# USB0_COMMON_0_VBP2APB_WRAP_CONTROLLER_VBP_CORE_ADDR_MAP register map
Vendor: Texas Instruments
Registers are 32-bit, access per field, reset 0x0 unless marked. A register's access mark holds for its fields unless they carry their own. Offsets are as the file gives them; [hi:lo] are bit positions; 'fields as' and 'values as' point back to an identical list.

## USB0_COMMON_0_VBP2APB_WRAP_CONTROLLER_VBP_CORE_ADDR_MAP (part 2 of 8)
0x00 VBP2APB_WRAP__CONTROLLER_VBP__CORE_ADDR_MAP_CDNS_DID ro reset 0x4024E
  [31:0] DID — Cadence Device ID Register IP4024E
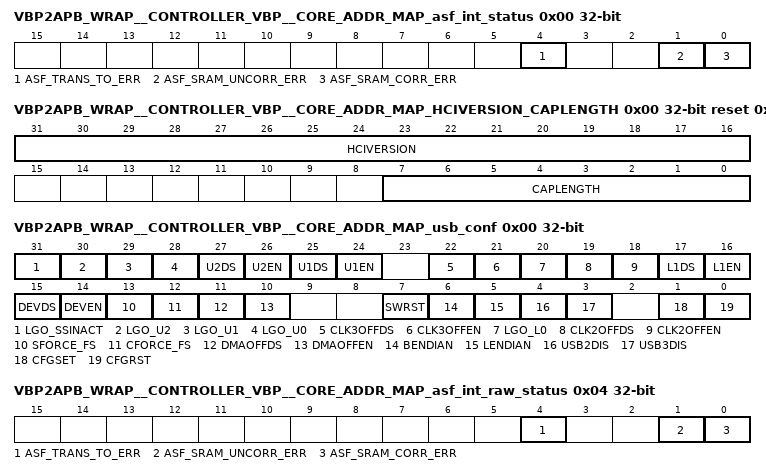
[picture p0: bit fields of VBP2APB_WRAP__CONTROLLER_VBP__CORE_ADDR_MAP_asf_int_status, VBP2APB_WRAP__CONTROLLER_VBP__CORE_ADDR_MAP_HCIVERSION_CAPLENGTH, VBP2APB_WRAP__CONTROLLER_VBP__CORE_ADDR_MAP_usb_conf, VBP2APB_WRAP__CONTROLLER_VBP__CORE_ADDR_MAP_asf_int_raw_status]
0x00 VBP2APB_WRAP__CONTROLLER_VBP__CORE_ADDR_MAP_asf_int_status access not given
  [4] ASF_TRANS_TO_ERR — Transaction timeouts error interrupt (access R/W1TC)
  [1] ASF_SRAM_UNCORR_ERR — SRAM uncorrectable error interrupt (access R/W1TC)
  [0] ASF_SRAM_CORR_ERR — SRAM correctable error interrupt (access R/W1TC)
0x00 VBP2APB_WRAP__CONTROLLER_VBP__CORE_ADDR_MAP_HCIVERSION_CAPLENGTH ro reset 0x1000080
  [31:16] HCIVERSION — Host Controller Interface Version Number [HCIVERSION]. This is a two-byte register containing a BCD encoding of the xHCI specification revision number supported by this host controller. The most significant byte of this register represents a major revision and the least significant byte is the minor revision. e.g. 0100h corresponds to xHCI version 1.0.
  [7:0] CAPLENGTH — Capability Registers Length [CAPLENGTH]. This register is used as an offset to add to register base to find the beginning of the Operational Register Space.
0x00 VBP2APB_WRAP__CONTROLLER_VBP__CORE_ADDR_MAP_usb_conf
  [31] LGO_SSINACT rw — SS.Inactive state entry request [SS mode only]. This bit can be used only if USBSS-DEV is part of the CDNS USB OTG Controller [USB_CAP.OTG_READY bit is 1 while reading]. In other cases should not be used and returns 0 when read. Writing '1' will trigger an attempt to perform transition to SS.Inactive state. Should be used only if Link is in U0 or Recovery state. This bit will be automatically cleared to '0' after link layer finishes SS.Inactive request. Result of the request [link layer enters SS.Inactive or not] can be verified by reading LTS [link state] field in USB_STS register. Writing '0' has no effect
  [30] LGO_U2 rw — U2 state entry request [SS mode only]. Writing '1' will trigger an attempt to perform transition to U2 state. This bit will be automatically cleared to '0' after link layer finishes U2 request. Result of the request [link layer enters U2 or not] can be verified by reading LTS [link state] field in USB_STS register. Writing '1' has no effect when USB_STS.LGOU2ENS is set to '0'. Writing '0' has no effect.
  [29] LGO_U1 rw — U1 state entry request [SS mode only]. Writing '1' will trigger an attempt to perform transition to U1 state. This bit will be automatically cleared to '0' after link layer finishes U1 request. Result of the request [link layer enters U1 or not] can be verified by reading LTS [link state] field in USB_STS register. Writing '1' has no effect when USB_STS.LGOU1ENS is set to '0'. Writing '0' has no effect.
  [28] LGO_U0 rw — U0 state entry request [SS mode only]. Writing '1' will trigger an attempt to perform transition to U0 state. If the link is suspended [U3 state] and CPU set this bit to'1', link will start driving resume signaling on its upstream link to indicate remote wakeup. The Function Wake Notification should be send using USB_CMD.SDNFW bit. Writing '0' has no effect.
  [27] U2DS wo — U2 state entry disable [SS mode only]. Writing '1' to this bit disables link layer from entering U2 state. Status of this bit can be checked in the USB_STS register. When both U2EN and U2DS bits are set to '1' while writing to USB_CONF register, the device behaviour is udefined. Writing '0' has no effect. This bit is always '0' while reading.
  [26] U2EN wo — U2 state entry enable [device side, SS mode only]. Writing '1' to this bit enables link layer to enter U2 state. Status of this bit can be checked in the USB_STS register. Writing '0' has no effect. When both U2EN and U2DS bits are set to '1' while writing to USB_CONF register, the device behaviour is udefined. This bit is always '0' while reading.
  [25] U1DS wo — U1 state entry disable [SS mode only]. Writing '1' to this bit disables link layer from entering U1 state. Status of this bit can be checked in the USB_STS register. Writing '0' has no effect. When both U1EN and U1DS bits are set to '1' while writing to USB_CONF register, none of the operations associated with these bits will be performed. This bit is always '0' while reading.
  [24] U1EN wo — U1 state entry enable [device side, SS mode only], Writing '1' to this bit enables link layer to enter U1 state. Status of this bit can be checked in the USB_STS register. Writing '0' has no effect. When both U1EN and U1DS bits are set to '1' while writing to USB_CONF register, none of the operations associated with these bits will be performed. This bit is always '0' while reading.
  [22] CLK3OFFDS wo — USB 3.0 clock gate enable. Writing '1' to this bit disables pclk clock turning-off when device enters U3 link state in SS mode. The actual 'USB 3.0 clock gate' status in can be checked in the USB_STS.USB3OFF register. When both CLK3OFFDS and CLK3OFFEN bits are set to '1' while writing to USB_CONF register, the device behaviour is udefined. This bit is always '0' while reading.
  [21] CLK3OFFEN wo — USB 3.0 clock gate disable. Writing '1' to this bit enables pclk clock turning-off when device enters U3 link state in SS mode. The actual 'USB 3.0 clock gate' status in can be checked in the USB_STS.USB3OFF register. When both CLK3OFFDS and CLK3OFFEN bits are set to '1' while writing to USB_CONF register, the device behaviour is udefined. This bit is always '0' while reading.
  [20] LGO_L0 rw — L0 LPM state entry request [HS/FS mode only]. Writing '1' will trigger an attempt to perform transition to L0 LPM state. This bit will be automatically cleared to '0' after LPM enter L0 state. Result of the request [LPM enters L0 or not] can be verified by reading LPMST [LPM state] field in USB_STS register. Writing '0' has no effect. If the LPM is suspended [L2 state] and CPU set this bit to'1', upstream will start driving resume signaling to indicate remote wakeup.
  [19] CLK2OFFDS wo — USB 2.0 clock gate enable. Writing '1' to this bit disables hsfs clock turning-off when device enters L2 LPM state in HS/FS mode. The actual 'USB 2.0 clock gate' status in can be checked in the USB_STS.USB2OFF register. When both CLK2OFFDS and CLK2OFFEN bits are set to '1' while writing to USB_CONF register, the device behaviour is udefined. This bit is always '0' while reading.
  [18] CLK2OFFEN wo — USB 2.0 clock gate disable. Writing '1' to this bit enables hsfs clock turning-off when device enters L2 LPM state in HS/FS mode. The actual 'USB 2.0 clock gate' status in can be checked in the USB_STS.USB2OFF register. When both CLK2OFFDS and CLK2OFFEN bits are set to '1' while writing to USB_CONF register, the device behaviour is udefined. This bit is always '0' while reading.
  [17] L1DS wo — L1 LPM state entry disable [HS/FS mode only]. Writing '1' to this bit disables USB2.0 LPM from entering L1 state. Status of this bit can be checked in the USB_STS register. Writing '0' has no effect. When both L1EN and L1DS bits are set to '1' while writing to USB_CONF register, the device behaviour is udefined. This bit is always '0' while reading.
  [16] L1EN wo — L1 LPM state entry enable [device side, HS/FS mode only]. Writing '1' to this bit enables USB2.0 LPM to enter L1 state. Status of this bit can be checked in the USB_STS register. Writing '0' has no effect. When both L1EN and L1DS bits are set to '1' while writing to USB_CONF register, the device behaviour is udefined. This bit is always '0' while reading.
  [15] DEVDS wo — Device disable. Writing '1' to the DEVDS bit sets to '0' the USB_STS.DEVS bit. Check also the DEVEN bit description. Writing '0' has no effect. This bit is always '0' while reading.
  [14] DEVEN wo — Device enable. After Power-On-Reset the USBSS_DEV is disconnected from the USB bus. To connect the device into the USB bus the software has to write '1' to DEVEN bit - this couse connection of the VBUS input to the internal device logic and connetion to the USB bus as a result [inside of USBSS_DEV an internal VBUS is used which which is the and gate: VBUS input AND USB_STS.DEVS bit in SFRs]. Writing '1' to the DEVEN bit sets to '1' the USB_STS.DEVS bit. Writing '0' has no effect. This bit is always '0' while reading.
  [13] SFORCE_FS wo — Set Force Full Speed. Writing '1' to this bit forces Full Speed when USBSS-DEV operates in USB2.0 mode [disables High Speed]. When both SFORCE_FS and CFORCE_FS bits are set to '1' while writing to USB_CONF register, the device behaviour is udefined. The status of this settings can be check in the USB_STS.DISABLE_HS bit. This bit is always '0' while reading.
  [12] CFORCE_FS wo — Clear Force Full Speed. Writing '1' to this bit stop forcing Full Speed when USBSS-DEV operates in USB2.0 mode [stop disabling High Speed]. When both SFORCE_FS and CFORCE_FS bits are set to '1' while writing to USB_CONF register, the device behaviour is udefined. The status of this settings can be check in the USB_STS.DISABLE_HS bit. This bit is always '0' while reading.
  [11] DMAOFFDS wo — DMA clock turn-off disable. Writing '1' to this bit disables DMA clock turning-off when device exits U0 link state in SuperSpeed mode. When both DMAOFFDS and DMAOFFEN bits are set to '1' while writing to USB_CONF register, the device behaviour is udefined. This bit is always '0' while reading.
  [10] DMAOFFEN wo — DMA clock turn-off enable. Writing '1' to this bit enables DMA clock turning-off when device exits U0 link state in SuperSpeed mode. When both DMAOFFDS and DMAOFFEN bits are set to '1' while writing to USB_CONF register, the device behaviour is udefined. This bit is always '0' while reading.
  [7] SWRST rw — Device software reset. When set to 1, the entire USBSS-DEV is reset. The SWRST resets most flip-flops in entire USBSS-DEV. This bit is also used to connect disconnected device. Writing '0' has no effect.
  [6] BENDIAN wo — Big Endian Access. Writing '1' to this bit sets Big Endian byte order for SFRs access. Writing '0' has no effect. When both LENDIAN and BENDIAN bits are set to '1' while writing to USB_CONF register, the device behaviour is udefined. This bit is always '0' while reading.
  [5] LENDIAN wo — Little Endian access. Writing '1' to this bit sets Little Endian byte order for SFRs access. By default [after hardware reset], USBSS-DEV acts as little-endian device. Writing '0' has no effect. When both LENDIAN and BENDIAN bits are set to '1' while writing to USB_CONF register, the device behaviour is udefined. This bit is always '0' while reading.
  [4] USB2DIS wo — Disconnect USB device in HS/FS. Writing '1' to this bit disconnects USB in HS/FS. The actual USB connection status in HS/FS can be checked in the USB_STS register. Writing '0' has no effect. To connect disconnected device, CPU performs software reset [UCB_CFG.SWRST]. This bit is always '0' while reading.
  [3] USB3DIS wo — Disconnect USB device in SuperSpeed. Writing '1' to this bit disconnects USB in Super Speed. The actual USB connection status in the SS mode can be checked in the USB_STS register. If link is in U3 [SuperSpeed PHY clock is disabled] while software writes USB3DIS bit, first the hardware automatically wakes up the PHY to the P2 to turn on the PHY clock [clklink], and second, all operations related to device disconnection cease. Writing '0' has no effect. To connect disconnected device, CPU performs software reset [UCB_CFG.SWRST]. This bit is always '0' while reading.
  [1] CFGSET wo — Set Configuration. Software writes '1' to this bit when it receives SET_CONFIGURATION request with non-zero configuration number. CPU sets this bit after setting requested configuration and before setting REQ_CMPL bit in the EP_CMD register. Configuration will be set internally in the hardware when REQ_CMPL bit will be set. Writing '0' has no effect. The actual configuration status can be checked in the USB_STS register. This bit is always '0' while reading.
  [0] CFGRST wo — Reset USB device configuration. Writing '1' to this bit resets USB device configuration, leaving only EP0 IN/OUT active [all other EP-related registers will be loaded with default values]. Any configuration/interface change, including adding new IF, must be preceded with configuration reset, adding current IF's as well as new IF. Writing '0' has no effect. This bit is always '0' while reading.
0x04 VBP2APB_WRAP__CONTROLLER_VBP__CORE_ADDR_MAP_CDNS_RID ro reset 0x200
  [15:0] CDNS_RID
0x04 VBP2APB_WRAP__CONTROLLER_VBP__CORE_ADDR_MAP_asf_int_raw_status access not given
  fields as VBP2APB_WRAP__CONTROLLER_VBP__CORE_ADDR_MAP_asf_int_status
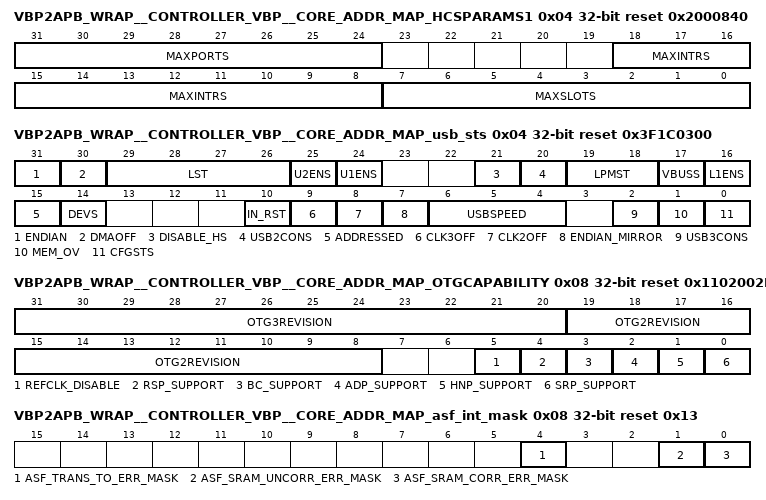
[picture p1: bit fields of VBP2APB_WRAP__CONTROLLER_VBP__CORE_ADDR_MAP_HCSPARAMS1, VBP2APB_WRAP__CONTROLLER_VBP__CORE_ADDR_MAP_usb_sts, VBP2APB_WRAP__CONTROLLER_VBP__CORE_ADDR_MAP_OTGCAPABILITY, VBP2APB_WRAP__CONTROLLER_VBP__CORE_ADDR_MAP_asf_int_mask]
0x04 VBP2APB_WRAP__CONTROLLER_VBP__CORE_ADDR_MAP_HCSPARAMS1 ro reset 0x2000840
  [31:24] MAXPORTS — Number of Ports [MaxPorts]. This field specifies the maximum Port Number value, i.e. the highest numbered Port Register Set that are addressable in the Operational Register Space. Valid values are in the range of 1h to FFh. The value in this field shall reflect the maximum Port Number value assigned by an xHCI Supported Protocol Capability, described in section 7.2 of xHCI specification. Software shall refer to these capabilities to identify whether a specific Port Number is valid, and the protocol supported by the associated Port Register Set.
  [18:8] MAXINTRS — Number of Interrupters [MaxIntrs]. This field specifies the number of Interrupters implemented on this host controller. Each Interrupter may be allocated to a MSI or MSI-X vector and controls its generation and moderation. The value of this field determines how many Interrupter Register Sets are addressable in the Runtime Register Space [refer to section 5.5 of xHCI specification]. Valid values are in the range of 1h to 400h. A '0' in this field is undefined.
  [7:0] MAXSLOTS — Number of Device Slots [MaxSlots]. This field specifies the maximum number of Device Context Structures and Doorbell Array entries this host controller can support. Valid values are in the range of 1 to 255. The value of 0 is reserved.
0x04 VBP2APB_WRAP__CONTROLLER_VBP__CORE_ADDR_MAP_usb_sts ro reset 0x3F1C0300
  [31] ENDIAN — SFR Endian status. Little/Big Endian byte order for SFR access: 0 - Little Endian order [default after hardware reset] 1 - Big Endian order
  [30] DMAOFF — DMA clock turn-off status. DMA clock turn-off/enable status: 0 - DMA clock is always on [default after hardware reset] 1 - DMA clock turn-off in U1, U2 and U3 [SS mode] is enabled.
  [29:26] LST — SuperSpeed Link LTSSM state. This field reflects USBSS-DEV current SuperSpeed link state: 0 - U0 State 1 - U1 State 2 - U2 State 3 - U3 State [Device Suspended] 4 - Disabled State 5 - RxDetect State 6 - Inactive State 7 - Polling State 8 - Recovery State 9 - Hot Reset State 10 - Compliance Mode State 11 - Loopback State 12:14 - Reserved 15 - Uninitialized
  [25] U2ENS — U2 state enable status [valid in SS mode only]: 0 - Entering to U2 state disabled 1 - Entering to U2 state enabled
  [24] U1ENS — U1 state enable status [valid in SS mode only]: 0 - Entering to U1 state disabled 1 - Entering to U1 state enabled
  [21] DISABLE_HS — DisableHS status [valid for HS/FS mode only] 0 - High Speed operations in USB2.0 [FS/HS] mode not disabled 1 - High Speed operations in USB2.0 [FS/HS] mode disabled
  [20] USB2CONS — HS/FS mode connection enable status [valid for HS/FS mode only]. 0 - the disconnect bit for HS/FS mode is set [USB_CONF.USB2DIS] 1 - the disconnect bit for HS/FS mode is not set [device can be connected in this mode] The actual connection status can be checked in the USB_STS.USBSPEED register
  [19:18] LPMST — HS/FS LPM state [valid for HS/FS mode only]. This field reflects USBSS-DEV current LPM [used in HS/FS mode] state: 0 - L0 State 1 - L1 State 2 - L2 State 3 - L3 State
  [17] VBUSS — Internal VBUS connection status. 0 - internal VBUS is not detected 1 - internal VBUS is detected
  [16] L1ENS — L1 LPM state enable status [valid for HS/FS mode only]. 0 - Entering to L1 LPM state disabled 1 - Entering to L1 LPM state enabled
  [15] ADDRESSED — Address status: 0 - USB device is default state 1 - USB device is at least in address state [Function Address was set by the SW]
  [14] DEVS — Device enable Status 0 - USB device is disabled [VBUS input is disconnected from internal logic] 1 - USB device is enabled [VBUS input is connected to the internal logic] This bit can be changed by setting DEVEN or DEVDS bits in USB_CONF register.
  [10] IN_RST — Controler in reset state. This bit indicate that whole [in case of POR] or part of controller [in case of SWRST or USB resets] currently is in reset state. As controller has registers in both clock domains [system, and USB], internal reset synchronization between these domains may take longer than the cause of the reset [e.g active reset_n input]. Thus it is recommended to check if controller is not in reset state, before software starts its operations [especially after POR]. 0 - Internal reset is active 1 - Internal reset is not active and controller is fully operational.
  [9] CLK3OFF — PCLK clock turn-off status. When CLK3OFF bit is '0', the phypowerdown output signal is not set to '11' in U3 link state, thus USB3.0 PHY does not turn off the pclk clock. 0 - pclk clock is always on 1 - pclk clock turn-off in U3 [SS mode] is enabled [default after hardware reset]
  [8] CLK2OFF — HS/FS clock turn-off status. When CLK2OFF bit is '0', the utmisuspendm output signal is not set low in USB2.0 suspend state [L2 state], thus USB2.0 PHY does not turn off the hsfs clock 0 - hsfs clock is always on 1 - hsfs clock turn-off in L2 [HS/FS mode] is enabled [default after hardware reset]
  [7] ENDIAN_MIRROR — Little/Big Endian byte order for SFR access. 0 - Little Endian order [default after hardware reset] 1 - Big Endian order Endian byte order for SFR access can be changed by setting BENDIAN or LEDNIAN bits in USB_CONF register.
  [6:4] USBSPEED — Device speed: 0: undef., 1: LowSpeed [not supported], 2: FullSpeed, 3: HighSpeed, 4: SuperSpeed, 5-7: Reserved
  [2] USB3CONS — SuperSpeed connection status. 0 - USB in SuperSpeed mode disconnected 1 - USB in SuperSpeed mode connected
  [1] MEM_OV — On-chip memory overflow. 0 - On-chip memory status OK 1 - On-chip memory overflow Memory overflow may occur if, during enumeration [SET_CONFIGURATION request] device software will try to turn on too many endpoints or will try to set too much endpoinds buffers [see EP_CFG.BUFFERING]. After each completion of enumeration software should check this bit, and when a memory overflow occurred, software must delete current configuration [using USB_CONF.CFGRST bit] and then set the one that requires less on-chip memory. For available memory calculation, the CDNS_USBSSDEV_ATTACHED_MEM_SIZE define parameter is used.
  [0] CFGSTS — Configuration status. 1 - device is in the configured state 0 - device is not configured This bit set during SET_CONFIGURATION request means that status stage of this request was finished successfully, thus device configuration was finished successfully.
0x08 VBP2APB_WRAP__CONTROLLER_VBP__CORE_ADDR_MAP_OTGCAPABILITY ro reset 0x1102002B
  [31:20] OTG3REVISION — Specifies implemeted OTG3.0 specification revision
  [19:8] OTG2REVISION — Specifies implemeted OTG2.0 specification revision
  [5] REFCLK_DISABLE — PHY Reference clock control disable. 0 - PHY Reference clock control supported 1 - PHY Reference clock control not supported
  [4] RSP_SUPPORT — RSP support. 0 - RSP not supported 1 - RSP supported
  [3] BC_SUPPORT — BC Support [Battery Charging specification rev 1.2]. 0 - BC not supported 1 - BC supported
  [2] ADP_SUPPORT — ADP support. 0 - ADP not supported 1 - ADP supported
  [1] HNP_SUPPORT — HNP support. 0 - HNP not supported 1 - HNP supported
  [0] SRP_SUPPORT — SRP support. 0 - SRP not supported 1 - SRP supported
0x08 VBP2APB_WRAP__CONTROLLER_VBP__CORE_ADDR_MAP_asf_int_mask reset 0x13
  [4] ASF_TRANS_TO_ERR_MASK rw — Mask bit for transaction timeouts error interrupt.
  [1] ASF_SRAM_UNCORR_ERR_MASK rw — Mask bit for SRAM uncorrectable error interrupt.
  [0] ASF_SRAM_CORR_ERR_MASK rw — Mask bit for SRAM correctable error interrupt.
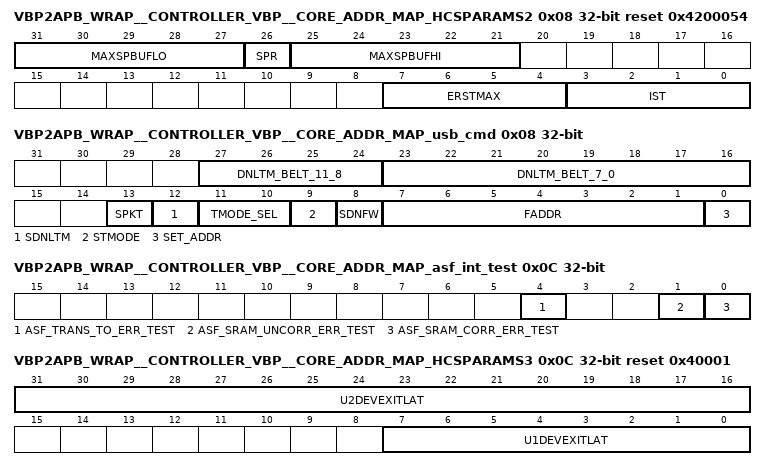
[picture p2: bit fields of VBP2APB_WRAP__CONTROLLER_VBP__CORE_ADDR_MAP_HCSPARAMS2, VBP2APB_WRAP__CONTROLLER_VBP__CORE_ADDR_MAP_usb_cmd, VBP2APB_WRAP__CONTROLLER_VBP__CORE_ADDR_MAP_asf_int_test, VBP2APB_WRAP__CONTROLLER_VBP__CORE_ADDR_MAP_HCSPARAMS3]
0x08 VBP2APB_WRAP__CONTROLLER_VBP__CORE_ADDR_MAP_HCSPARAMS2 ro reset 0x4200054
  [31:27] MAXSPBUFLO — Max Scratchpad Buffers [Max Scratchpad Bufs Lo]. Default = implementation dependent. Valid values for Max Scratchpad Buffers [Hi and Lo] are 0-1023. This field indicates the low order 5 bits of the number of Scratchpad Buffers system software shall reserve for the xHC. Refer to section 4.20 of xHCI specification for more information.
  [26] SPR — Scratchpad Restore [SPR]. Default = implementation dependent. If Max Scratchpad Buffers is > 0 then this flag indicates whether the xHC uses the Scratchpad Buffers for saving state when executing Save and Restore State operations. If Max Scratchpad Buffers is = 0 then this flag shall be 0. Refer to section 4.23.2 of xHCI specification for more information. A value of '1' indicates that the xHC requires the integrity of the Scratchpad Buffer space to be maintained across power events. A value of '0' indicates that the Scratchpad Buffer space may be freed and reallocated between power events.
  [25:21] MAXSPBUFHI — Max Scratchpad Buffers [Max Scratchpad Bufs Hi]. Default = implementation dependent. This field indicates the high order 5 bits of the number of Scratchpad Buffers system software shall reserve for the xHC. Refer to section 4.20 of xHCI specification for more information.
  [7:4] ERSTMAX — Event Ring Segment Table Max [ERST Max]. Default = implementation dependent. Valid values are 0-15. This field determines the maximum value supported the Event Ring Segment Table Base Size registers [5.5.2.3.1], where: The maximum number of Event Ring Segment Table entries = 2 ^[ERSTMax], e.g. if the ERST Max = 7, then the xHC Event Ring Segment Table[s] supports up to 128 entries, 15 then 32K entries, etc.
  [3:0] IST — Isochronous Scheduling Threshold [IST]. Default = implementation dependent. The value in this field indicates to system software the minimum distance [in time] that it is required to stay ahead of the host controller while adding TRBs, in order to have the host controller process them at the correct time. The value shall be specified in terms of number of frames/microframes. If bit [3] of IST is cleared to '0', software can add a TRB no later than IST[2:0] Microframes before that TRB is scheduled to be executed. If bit [3] of IST is set to '1', software can add a TRB no later than IST[2:0] Frames before that TRB is scheduled to be executed. Refer to Section 4.14.2 of xHCI specification for details on how software uses this information for scheduling isochronous transfers.
0x08 VBP2APB_WRAP__CONTROLLER_VBP__CORE_ADDR_MAP_usb_cmd
  [27:24] DNLTM_BELT_11_8 wo — Device Notification 'Latency Tolerance Message' - BELT value [11:8] [SS mode only]. If user writes '1' to SDNLTM bit, the device will send Device Notification 'Latency Tolerance Message' with 'BELT[11:8]' field value equal to DNLTM_BELT_11_8. This field must be filled up before the USB_CMD.SDNLTM bit is set, and cannot be changed while USB_CMD.SDNLTM bit is not zero [Device Notification is being sent by the device controller] This field is always '0' while reading.
  [23:16] DNLTM_BELT_7_0 wo — Device Notification 'Latency Tolerance Message' - BELT value [7:0] / Device Notification 'Function Wake' - Interface value [SS mode only]. This field must be filled up before one of the USB_CMD.SDNLTM/SDNFW bits is set, and cannot be changed while USB_CMD.SDNLTM/SDNFW bits are not zero [Device Notification is being sent by the device controller]. If user writes '1' to SDNFW bit the device will send Device Notification 'Function Wake' with 'Interface[7:0]' field value equal to DNLTM_BELT_7_0. If user writes '1' to SDNLTM bit, the device will send Device Notification 'Latency Tolerance Message' with 'BELT[7:0]' field value equal to DNLTM_BELT_7_0. This field is always '0' while reading.
  [13] SPKT rw — Send Custom Transaction Packet [SS mode only] Writing '1' will trigger an attempt to send Custom TP as defined in the USB3.0 specification. The packet contents that will be send as TP to the host must be previously prepared in the CPKT1 [will be sent as DWORD 0 in the TP], CPKT2 [will be sent as DWORD 1 in the TP] and CPKT3 [will be sent as DWORD 2 in the TP] registers. Note that TP DWORD 3 will be automatically inserted by the device controller. This bit will be automatically cleared if this TP is sent and only then the new Custom TP [by means of SPKT bit] or other Notification TP [by means of SDNLTM or SDNFW bits] can be send again. Writing 0 has no effect. This bit cannot be written by 1 simultaneously with SDNLTM and SDNFW bits.
  [12] SDNLTM rw — Send Latency Tolerance Message Device Notification TP [SS mode only]. Writing '1' will trigger an attempt to send Device Notification 'Latency Tolerance Message' with 'BELT' field set to DNLTM_BELT. This bit will be automatically cleared if the LTM Notification TP is sent and only then the new LTM Notification TP or the other TP [by means of SPKT or SDNFW bits] can be send again. Writing '0' has no effect. This bit cannot be written by '1' simultaneously with SPKT and SDNFW bits.
  [11:10] TMODE_SEL wo — Test mode selector [HS/FS mode only]. This field contains selected Test Mode - Device will enter this Test mode when '1' is written to STMODE. USB 2.0 Test mode selector: 00 - Test_J, 01 - Test_K, 10 - Test_SE0_NAK, 11 - Test_Packet This field is always '0' while reading.
  [9] STMODE wo — Set Test Mode [HS/FS mode only]. Writing the value '1 'to this bit causes the device enters into test mode selected by the TMODE_SEL field. Writing '0' has no effect. This bit is always '0' while reading.
  [8] SDNFW rw — Send Function Wake Device Notification TP [SS mode only]. Writing '1' will trigger an attempt to send 'Device Notification' with 'Interface' field set to DNFW_INT. This bit will be automatically cleared if the FW Notification TP is sent and only then the new FW Notification TP or the other TP [by means of SPKT or SDNLTM bits] can be send again. Writing '0' has no effect. This bit cannot be written by '1' simultaneously with SPKT and SDNLTM bits.
  [7:1] FADDR wo — Function Address. This field is saved to the device only when the field SET_ADDR is set '1 ' during write to USB_CMD register. Software is responsible for entering the address of the device during SET_ADDRESS request service. This field should be set immediately after the SETUP packet is decoded, and prior to confirmation of the status phase [what is done by bit EP_CMD.REQ_CMPL] Verify that the device successfully completed the SET_ADDRESS request and is in ADRESSED state [as defined in USB3 spec] can be realized by checking the bit USB_STS. ADRESSED. USB_CMD.FADDR field can also be read at any time. This field is always '0' while reading.
  [0] SET_ADDR wo — Set Function Address. Writing the value '1 'to this bit causes the device is assigned to the USB Function Address according to the FADDR field. The device address must be saved by software when operating SET_ADDRESS request. After saving device address, software should set the EP_CMD.ERDY bit [as with all other requests] to quit the setup phase and then set bit EP_CMD.REQ_CMPL to confirm the status of the host phase. Writing '0 'has no effect. This bit is always '0' while reading.
0x0C VBP2APB_WRAP__CONTROLLER_VBP__CORE_ADDR_MAP_asf_int_test
  [4] ASF_TRANS_TO_ERR_TEST wo — Test bit for transaction timeouts error interrupt.
  [1] ASF_SRAM_UNCORR_ERR_TEST wo — Test bit for SRAM uncorrectable error interrupt.
  [0] ASF_SRAM_CORR_ERR_TEST wo — Test bit for SRAM correctable error interrupt.
0x0C VBP2APB_WRAP__CONTROLLER_VBP__CORE_ADDR_MAP_HCSPARAMS3 ro reset 0x40001
  [31:16] U2DEVEXITLAT — U2 Device Exit Latency. Worst case latency to transition from U2 to U0. Applies to all root hub ports. The following are permissible values: 0000h Zero, 0001h Less than 1 s., 0002h Less than 2 s., ... 07FFh Less than 2047 s., 0800-FFFFh Reserved
  [7:0] U1DEVEXITLAT — U1 Device Exit Latency. Worst case latency to transition a root hub Port Link State [PLS] from U1 to U0. Applies to all root hub ports. The following are permissible values: 00h Zero, 01h Less than 1 s., 02h Less than 2 s., ... 0Ah Less than 10 s., 0B-FFh Reserved.
0x0C VBP2APB_WRAP__CONTROLLER_VBP__CORE_ADDR_MAP_usb_iptn ro
  [13:0] ITPN — ITP[SS] / SOF [HS/FS] number. In SS mode this field represent number of last ITP received from host. In HS/FS mode this field represent number of last SOF received from host.
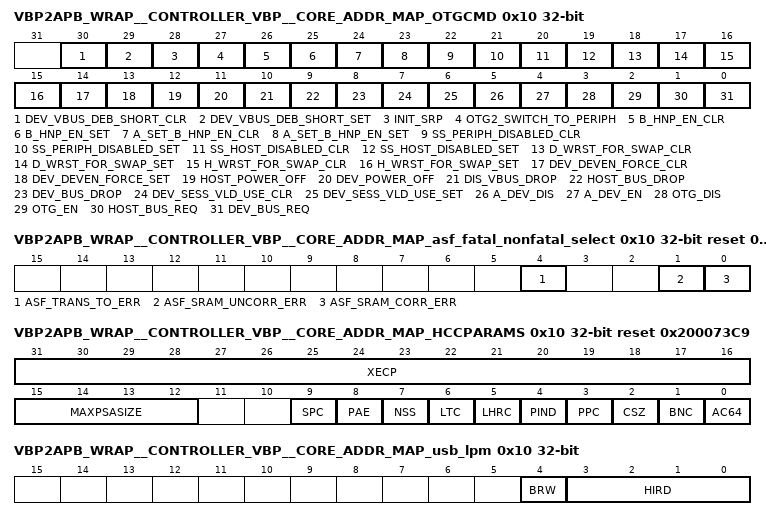
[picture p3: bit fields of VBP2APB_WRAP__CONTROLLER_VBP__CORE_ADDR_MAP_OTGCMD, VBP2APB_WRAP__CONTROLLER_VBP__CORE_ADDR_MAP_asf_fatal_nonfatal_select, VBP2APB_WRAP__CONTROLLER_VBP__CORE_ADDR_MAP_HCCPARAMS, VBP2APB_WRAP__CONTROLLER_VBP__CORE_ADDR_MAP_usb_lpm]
0x10 VBP2APB_WRAP__CONTROLLER_VBP__CORE_ADDR_MAP_OTGCMD
  [30] DEV_VBUS_DEB_SHORT_CLR wo — Disable forcing Device short VBUS debounce time. Setting this bit causes DEV_VBUS_DEB_SHORT bit in OTGSTS clear.
  [29] DEV_VBUS_DEB_SHORT_SET wo — Enable forcing Device short VBUS debounce time. This bit should be set while switching from Host to Device mode takes place. Setting this bit should be done in the same time when Device mode is activated [DEV_BUS_REQ]. Setting this bit causes DEV_VBUS_DEB_SHORT bit in OTGSTS set.
  [28] INIT_SRP wo — Initiate SRP
  [27] OTG2_SWITCH_TO_PERIPH wo — Switch to Peripheral mode when operating at USB 2.0
  [26] B_HNP_EN_CLR wo — This bit should be written if software wants to clear b_hnp_enable
  [25] B_HNP_EN_SET wo — This bit should be written if SetFeature[b_hnp_enable] has been accepted.
  [24] A_SET_B_HNP_EN_CLR wo — This bit should be written if upcoming USB 2.0 bus suspend should not cause Role Swap.
  [23] A_SET_B_HNP_EN_SET wo — This bit should be written if SetFeature[b_hnp_enable] has been sent.
  [22] SS_PERIPH_DISABLED_CLR wo — Enable SuperSpeed peripheral device functionality.
  [21] SS_PERIPH_DISABLED_SET wo — Disable SuperSpeed peripheral device functionality. Can be used only if Peripheral mode is not active.
  [20] SS_HOST_DISABLED_CLR wo — Enable SuperSpeed host functionality.
  [19] SS_HOST_DISABLED_SET wo — Disable SuperSpeed host functionality. Can be used only if Host mode is not active.
  [18] D_WRST_FOR_SWAP_CLR wo — Upcoming received Warm Reset should not be treated as Role Swapping indication. This bit should be set after Warm Reset for Role Swap is received on the Port
  [17] D_WRST_FOR_SWAP_SET wo — Upcoming Warm Reset will be received for Role Swapping. This bit should be set before Warm Reset for Role Swap is received on the Port
  [16] H_WRST_FOR_SWAP_CLR wo — Upcoming Warm Reset will not be generated for Role Swapping. This bit should be set after Warm Reset for Role Swap is generated on the Port
  [15] H_WRST_FOR_SWAP_SET wo — Upcoming Warm Reset will be generated for Role Swapping. This bit should be set before Warm Reset for Role Swap is generated on the Port
  [14] DEV_DEVEN_FORCE_CLR wo — Clear forcing Device DEVEN bit to 1. Setting this bit causes DEV_DEVEN_FORCE bit in OTGSTS clear.
  [13] DEV_DEVEN_FORCE_SET wo — Set forcing Device DEVEN bit to 1. This bit may be set while switching from Host to Device mode takes place. Setting this bit should be done in the same time when Device mode is activated [DEV_BUS_REQ]. Setting this bit causes DEV_DEVEN_FORCE bit in OTGSTS set.
  [12] HOST_POWER_OFF wo — Power Down CDNSXHCI.
  [11] DEV_POWER_OFF wo — Power Down USBSS-DEV.
  [10] DIS_VBUS_DROP wo — Do not disable vbus while bus is dropped. This bit is valid only if DEV_BUS_DROP or HOST_BUS_DROP are set.
  [9] HOST_BUS_DROP wo — Drop the bus for Host mode. This bit should be set when Host mode is no longer needed. It will clear HOST_ACTIVE bit is OTGSTS register
  [8] DEV_BUS_DROP wo — Drop the bus for Device mode. This bit should be set when Device mode is no longer needed. It will clear DEV_ACTIVE bit is OTGSTS register
  [7] DEV_SESS_VLD_USE_CLR wo — Device should use a_vbus_vld as vbus valid indication. This bit should be set in the same time when DEV_BUS_REQ
  [6] DEV_SESS_VLD_USE_SET wo — Device should use b_sess_vld as vbus valid indication. This bit should be set in the same time when DEV_BUS_REQ
  [5] A_DEV_DIS wo — Configure OTG as B-Device. It is only valid if OTG mode is enabled. This bit should be set in the same time when OTG_EN
  [4] A_DEV_EN wo — Configure OTG as A-Device. It is only valid if OTG mode is enabled. This bit should be set in the same time when OTG_EN
  [3] OTG_DIS wo — Disable OTG mode. It will clear OTG_IS_ENABLED bit is OTGSTS register
  [2] OTG_EN wo — Enable OTG mode. It will set OTG_IS_ENABLED bit is OTGSTS register
  [1] HOST_BUS_REQ wo — Request the bus for Host mode. It will set HOST_ACTIVE bit is OTGSTS register
  [0] DEV_BUS_REQ wo — Request the bus for Device mode. It will set DEV_ACTIVE bit is OTGSTS register
0x10 VBP2APB_WRAP__CONTROLLER_VBP__CORE_ADDR_MAP_asf_fatal_nonfatal_select reset 0x13
  [4] ASF_TRANS_TO_ERR rw — Enable transaction timeouts error interrupt as fatal.
  [1] ASF_SRAM_UNCORR_ERR rw — Enable SRAM uncorrectable error interrupt as fatal.
  [0] ASF_SRAM_CORR_ERR rw — Enable SRAM correctable error interrupt as fatal.
0x10 VBP2APB_WRAP__CONTROLLER_VBP__CORE_ADDR_MAP_HCCPARAMS ro reset 0x200073C9
  [31:16] XECP — xHCI Extended Capabilities Pointer [xECP]. This field indicates the existence of a capabilities list. The value of this field indicates a relative offset, in 32-bit words, from Base to the beginning of the first extended capability. For example, using the offset of Base is 1000h and the xECP value of 0068h, we can calculate the following effective address of the first extended capability: 1000h + [0068h shifted left 2] -> 1000h + 01A0h -> 11A0h
  [15:12] MAXPSASIZE — Maximum Primary Stream Array Size [MaxPSASize]. This fields identifies the maximum size Primary Stream Array that the xHC supports. The Primary Stream Array size = 2^[MaxPSASize+1]. Valid MaxPSASize values are 0 to 15, where 0 indicates that Streams are not supported.
  [9] SPC — Stopped - Short Packet Capability [SPC]. This flag indicates that the host controller implementation is capable of generating a Stopped - Short Packet Completion Code. Refer to section 4.6.9 of xHCI specification for more information.
  [8] PAE — Parse All Event Data [PAE]. This flag indicates whether the host controller implementation Parses all Event Data TRBs while advancing to the next TD after a Short Packet, or it skips all but the first Event Data TRB. A '1' in this bit indicates that all Event Data TRBs are parsed. A '0' in this bit indicates that only the first Event Data TRB is parsed [refer to section 4.10.1.1 of xHCI specification].
  [7] NSS — No Secondary SID Support [NSS]. This flag indicates whether the host controller implementation supports Secondary Stream IDs. A '1'in this bit indicates that Secondary Stream ID decoding is not supported. A '0' in this bit indicates that Secondary Stream ID decoding is supported. [refer to Sections 4.12.2 and 6.2.3 of xHCI specification].
  [6] LTC — Latency Tolerance Messaging Capability [LTC]. This flag indicates whether the host controller implementation supports Latency Tolerance Messaging [LTM]. A '1' in this bit indicates that LTM is supported. A 0 in this bit indicates that LTM is not supported. Refer to section 4.13.1 of xHCI specification for more information on LTM.
  [5] LHRC — Light HC Reset Capability [LHRC]. This flag indicates whether the host controller implementation supports a Light Host Controller Reset. A '1' in this bit indicates that Light Host Controller Reset is supported. A '0' in this bit indicates that Light Host Controller Reset is not supported. The value of this flag affects the functionality of the Light Host Controller Reset [LHCRST] flag in the USBCMD register [refer to Section 5.4.1 of xHCI specification].
  [4] PIND — Port Indicators [PIND]. This bit indicates whether the xHC root hub ports support port indicator control. When this bit is a '1', the port status and control registers include a read/writeable field for controlling the state of the port indicator. Refer to Section 5.4.8 of xHCI specification for definition of the Port Indicator Control field [PIC field of PORTSC register].
  [3] PPC — Port Power Control [PPC]. This flag indicates whether the host controller implementation includes port power control. A '1' in this bit indicates the ports have port power switches. A '0' in this bit indicates the port do not have port power switches. The value of this flag affects the functionality of the PP flag in each port status and control register [refer to Section 5.4.8 of xHCI specification]. When DEBUG_CTRL_REG capability is used [CDNS_RM_CBIT_DEBUG_CTRL_REG is not defined] then this bit is treated as RW. Its value can be changed only by writes to bit 8 of DEBUG_CTRL_REG [port_pwr_ctrl_toggle]. Direct writes to this bit are not possible.
  [2] CSZ — Context Size [CSZ]. If this bit is set to '1', then the xHC uses 64 byte Context data structures. If this bit is cleared to 0, then the xHC uses 32 byte Context data structures. Note: This flag does not apply to Stream Contexts.
  [1] BNC — BW Negotiation Capability [BNC]. This flag identifies whether the xHC has implemented the Bandwidth Negotiation. Values for this flag have the following interpretation: '0': BW Negotiation not implemented '1': BW Negotiation implemented Refer to section 4.16 of xHCI specification for more information on Bandwidth Negotiation.
  [0] AC64 — 64-bit Addressing Capability [AC64]. This flag documents the addressing range capability of this implementation. The value of this flag determines whether the xHC has implemented the high order 32 bits of 64 bit register and data structure pointer fields. Values for this flag have the following interpretation: '0': 32-bit address memory pointers implemented, '1': 64-bit address memory pointers implemented. If 32-bit address memory pointers are implemented, the xHC shall ignore the high order 32 bits of 64 bit data structure pointer fields, and system software shall ignore the high order 32 bits of 64 bit xHC registers.
0x10 VBP2APB_WRAP__CONTROLLER_VBP__CORE_ADDR_MAP_usb_lpm ro
  [4] BRW — Remote Wakeup Enable [bRemoteWake]
  [3:0] HIRD — Host Initiated Resume Duration. This is the Resume duration from L1 LPM state, received from the host in the latest Extended Token packet. For more information see chapter: 'HS/FS mode - Link Power Management'
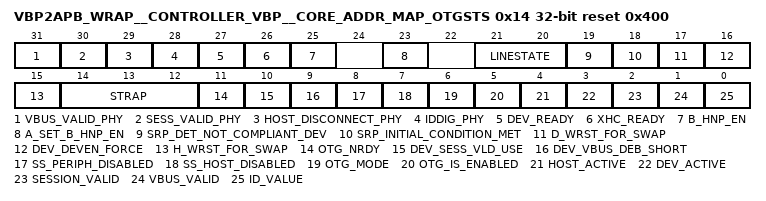
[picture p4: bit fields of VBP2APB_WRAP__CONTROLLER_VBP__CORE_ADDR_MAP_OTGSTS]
0x14 VBP2APB_WRAP__CONTROLLER_VBP__CORE_ADDR_MAP_OTGSTS ro reset 0x400
  [31] VBUS_VALID_PHY — PHY VBUS valid comparator status
  [30] SESS_VALID_PHY — PHY Session valid comparator status
  [29] HOST_DISCONNECT_PHY — PHY hostdisconnect status
  [28] IDDIG_PHY — PHY UTMI iddig status
  [27] DEV_READY — Device mode is turned on. registers in USBSS-DEV domain are accessible through APB
  [26] XHC_READY — Host mode is turned on. registers in CDNSXHCI AUX domain are accessible through APB
  [25] B_HNP_EN — SetFeature[b_hnp_enable] has been accepted.
  [23] A_SET_B_HNP_EN — SetFeature[b_hnp_enable] has been sent and is valid.
  [21:20] LINESTATE — PHY UTMI linestate status
  [19] SRP_DET_NOT_COMPLIANT_DEV — OTG A-device detected not compilant device. If this bit is set then OTG A-device should disable SRP detection until not compilant device is disconnected [SRP_NOT_COMP_DEV_REMOVED_INT]
  [18] SRP_INITIAL_CONDITION_MET — SRP initial condition are met. OTG B-device software should issue SRP puluse onli if this bit is set.
  [17] D_WRST_FOR_SWAP — Upcoming Warm Reset will be received for Role Swapping from Peripheral to Host.
  [16] DEV_DEVEN_FORCE — Device forcing DEVEN bit is enabled.
  [15] H_WRST_FOR_SWAP — Upcoming Warm Reset will be generated for Role Swapping from Host to Peripheral.
  [14:12] STRAP — Value of the strap pins. 000 - no default configuration 010 - Controller initiall configured as Host 100 - Controller initially configured as Device other - Reserved [might be used for Type-C]
  [11] OTG_NRDY — OTG Controller not ready. Software shall not read nor write any register except OTGISTS if this bit is set.
  [10] DEV_SESS_VLD_USE — Device mode vbus valid indication: 0: a_vbus_vld is used as vbus valid 1: b_sess_vld is used as vbus valid
  [9] DEV_VBUS_DEB_SHORT — Device forcing short VBUS decounce is enabled.
  [8] SS_PERIPH_DISABLED — SuperSpeed device functionality is disabled. Port will be operating at USB 2.0 speed.
  [7] SS_HOST_DISABLED — SuperSpeed host functionality is disabled. Port will be operating at USB 2.0 speed.
  [6] OTG_MODE — OTG mode: 0 - A-Device 1 - B-Device Valid only if OTG_IS_ENABLED is 1.
  [5] OTG_IS_ENABLED — OTG functionality is enabled
  [4] HOST_ACTIVE — Device mode is active. NOTE: It is possible that Host is in inactive state [even turned off] while HOST_ACTIVE is 1.
  [3] DEV_ACTIVE — Device mode is active. NOTE: It is possible that Device is in inactive state [even turned off] while DEV_ACTIVE is 1.
  [2] SESSION_VALID — The sessionvalid status visible to the controller
  [1] VBUS_VALID — The vbusvalid status visible to the controller
  [0] ID_VALUE — Current value of the ID pin visible to the controller. It is only valid when idpullup in PORTOVERRIDE_TYPE register is set to '1'. ID_VALUE must be valid within 50ms after idpullup is set to '1'
